CM_ "IMPORT _toyota_2017.dbc";
CM_ "IMPORT _toyota_adas_standard.dbc";

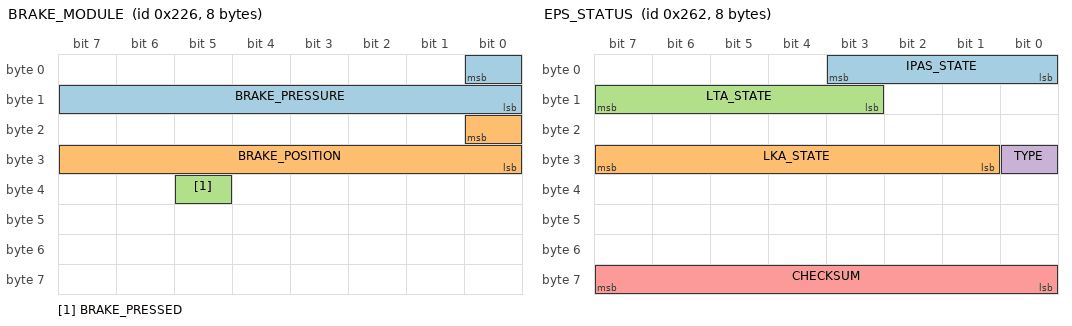
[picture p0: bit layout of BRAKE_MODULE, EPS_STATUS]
BO_ 550 BRAKE_MODULE: 8 XXX
 SG_ BRAKE_PRESSURE : 0|9@0+ (1,0) [0|511] "" XXX
 SG_ BRAKE_POSITION : 16|9@0+ (1,0) [0|511] "" XXX
 SG_ BRAKE_PRESSED : 37|1@0+ (1,0) [0|1] "" XXX

BO_ 610 EPS_STATUS: 8 EPS
 SG_ IPAS_STATE : 3|4@0+ (1,0) [0|15] "" XXX
 SG_ LKA_STATE : 31|7@0+ (1,0) [0|127] "" XXX
 SG_ LTA_STATE : 15|5@0+ (1,0) [0|31] "" XXX
 SG_ TYPE : 24|1@0+ (1,0) [0|1] "" XXX
 SG_ CHECKSUM : 63|8@0+ (1,0) [0|255] "" XXX

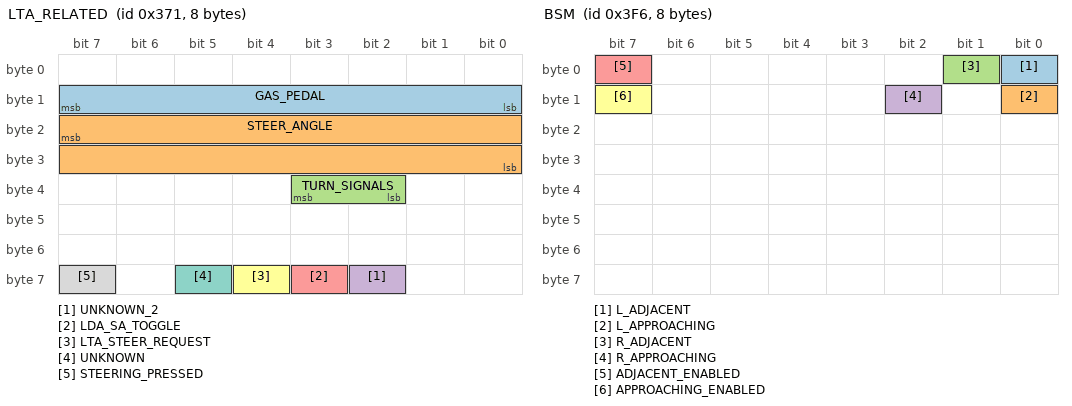
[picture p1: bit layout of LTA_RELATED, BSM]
BO_ 881 LTA_RELATED: 8 FCM
 SG_ GAS_PEDAL : 15|8@0+ (0.005,0) [0|1] "" XXX
 SG_ STEER_ANGLE : 23|16@0- (0.0573,0) [-500|500] "" XXX
 SG_ TURN_SIGNALS : 35|2@0+ (1,0) [0|3] "" XXX
 SG_ UNKNOWN_2 : 58|1@0+ (1,0) [0|1] "" XXX
 SG_ LDA_SA_TOGGLE : 59|1@0+ (1,0) [0|1] "" XXX
 SG_ LTA_STEER_REQUEST : 60|1@0+ (1,0) [0|1] "" XXX
 SG_ UNKNOWN : 61|1@0+ (1,0) [0|1] "" XXX
 SG_ STEERING_PRESSED : 63|1@0+ (1,0) [0|1] "" XXX

BO_ 1014 BSM: 8 XXX
 SG_ L_ADJACENT : 0|1@0+ (1,0) [0|1] "" XXX
 SG_ L_APPROACHING : 8|1@0+ (1,0) [0|1] "" XXX
 SG_ R_ADJACENT : 1|1@0+ (1,0) [0|1] "" XXX
 SG_ R_APPROACHING : 10|1@0+ (1,0) [0|1] "" XXX
 SG_ ADJACENT_ENABLED : 7|1@0+ (1,0) [0|1] "" XXX
 SG_ APPROACHING_ENABLED : 15|1@0+ (1,0) [0|1] "" XXX

CM_ SG_ 550 BRAKE_PRESSURE "seems prop to pedal force";
CM_ SG_ 550 BRAKE_POSITION "seems proportional to pedal displacement, unclear the max value of 0x1c8";
CM_ SG_ 610 TYPE "seems 1 on Corolla, 0 on all others";
CM_ SG_ 881 GAS_PEDAL "not set on all cars, only seen on TSS 2.5 Camry Hybrid so far";
CM_ SG_ 881 STEER_ANGLE "matches STEER_TORQUE_SENSOR->STEER_ANGLE";
CM_ SG_ 881 TURN_SIGNALS "flipped on some cars";
CM_ SG_ 881 LDA_SA_TOGGLE "not applicable for all cars";
CM_ SG_ 881 LTA_STEER_REQUEST "only applicable for TSS 2.5: matches STEERING_LTA->STEER_REQUEST";
CM_ SG_ 881 UNKNOWN "related to steering wheel angle";
CM_ SG_ 881 STEERING_PRESSED "only applicable for TSS 2.5: low sensitivity steering wheel pressed by driver signal";
CM_ SG_ 1014 L_ADJACENT "vehicle adjacent left side of car. enabled above 10mph, regardless of ADJACENT_ENABLED or APPROACHING_ENABLED";
CM_ SG_ 1014 L_APPROACHING "vehicle approaching from left side of car. enabled above 10mph, regardless of ADJACENT_ENABLED or APPROACHING_ENABLED";
CM_ SG_ 1014 R_ADJACENT "vehicle adjacent right side of car. enabled above 10mph, regardless of ADJACENT_ENABLED or APPROACHING_ENABLED";
CM_ SG_ 1014 R_APPROACHING "vehicle approaching from right side of car. enabled above 10mph, regardless of ADJACENT_ENABLED or APPROACHING_ENABLED";
CM_ SG_ 1014 ADJACENT_ENABLED "when BSM is enabled in settings, this is on along with APPROACHING_ENABLED. this controls bsm alert visibility";
CM_ SG_ 1014 APPROACHING_ENABLED "when BSM is enabled in settings, this is on along with ADJACENT_ENABLED. this controls bsm alert visibility";

VAL_ 610 IPAS_STATE 5 "override" 3 "enabled" 1 "disabled";
VAL_ 610 LKA_STATE 25 "temporary_fault" 17 "permanent_fault" 11 "lka_missing_unavailable2" 9 "temporary_fault2" 5 "active" 3 "lka_missing_unavailable" 1 "standby";
VAL_ 610 LTA_STATE 25 "temporary_fault" 9 "temporary_fault2" 5 "active" 3 "lta_missing_unavailable" 1 "standby";
